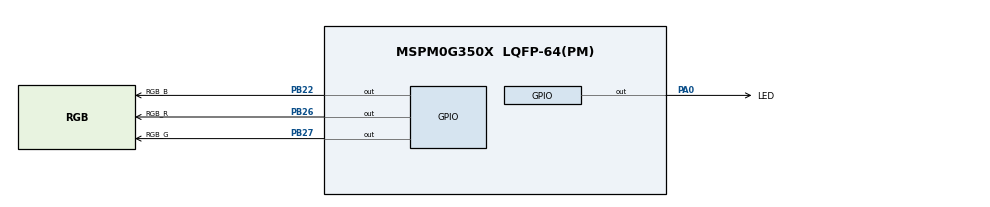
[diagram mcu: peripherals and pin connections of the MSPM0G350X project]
/**
 * @cliArgs --device "MSPM0G350X" --package "LQFP-64(PM)" --part "Default" --product "mspm0_sdk@2.01.00.03"
 * @versions {"tool":"1.20.0+3587"}
 */

/**
 * Import the modules used in this configuration.
 */
const Board         = scripting.addModule("/ti/driverlib/Board");
const GPIO          = scripting.addModule("/ti/driverlib/GPIO", {}, false);
const GPIO1         = GPIO.addInstance();
const GPIO2         = GPIO.addInstance();
const SYSCTL        = scripting.addModule("/ti/driverlib/SYSCTL");
const ProjectConfig = scripting.addModule("/ti/project_config/ProjectConfig");

/**
 * Write custom configuration values to the imported modules.
 */
Board.peripheral.$assign = "DEBUGSS";

GPIO1.$name                          = "PORTA";
GPIO1.port                           = "PORTA";
GPIO1.associatedPins[0].$name        = "LED";
GPIO1.associatedPins[0].initialValue = "SET";
GPIO1.associatedPins[0].pin.$assign  = "PA0";

GPIO2.$name                         = "PORTB";
GPIO2.port                          = "PORTB";
GPIO2.associatedPins.create(3);
GPIO2.associatedPins[0].$name       = "RGB_R";
GPIO2.associatedPins[0].pin.$assign = "PB26";
GPIO2.associatedPins[1].$name       = "RGB_G";
GPIO2.associatedPins[1].pin.$assign = "PB27";
GPIO2.associatedPins[2].$name       = "RGB_B";
GPIO2.associatedPins[2].pin.$assign = "PB22";

SYSCTL.clockTreeEn = true;

ProjectConfig.deviceSpin = "MSPM0G3507";

/**
 * Pinmux solution for unlocked pins/peripherals. This ensures that minor changes to the automatic solver in a future
 * version of the tool will not impact the pinmux you originally saw.  These lines can be completely deleted in order to
 * re-solve from scratch.
 */
Board.peripheral.swclkPin.$suggestSolution = "PA20";
Board.peripheral.swdioPin.$suggestSolution = "PA19";
